# M051DN_v1 register map
File version: 1.0
Registers are 32-bit, read-write, reset 0x0 unless marked. A register's access mark holds for its fields unless they carry their own. Offsets are from the block's base; [hi:lo] are bit positions; 'fields as' and 'values as' point back to an identical list.

## SPI0 — SPI Register Map
Base 0x40030000
Same registers: SPI1 0x40034000
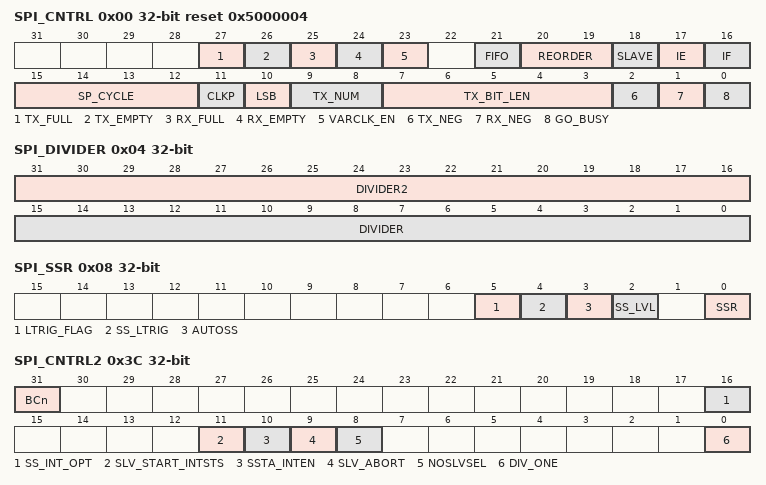
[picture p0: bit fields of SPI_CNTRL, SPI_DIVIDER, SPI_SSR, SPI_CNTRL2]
0x00 SPI_CNTRL reset 0x5000004 — Control and Status Register
  [27] TX_FULL ro — Transmit FIFO Buffer Full Indicator (Read Only) (M05xxDN/DE Only). It is a mutual mirror bit of SPI_STATUS[27].
    0=Indicates that the transmit FIFO buffer is not full; 1=Indicates that the transmit FIFO buffer is full
  [26] TX_EMPTY ro — Transmit FIFO Buffer Empty Indicator (Read Only) (M05xxDN/DE Only). It is a mutual mirror bit of SPI_STATUS[26].
    0=Indicates that the transmit FIFO buffer is not empty; 1=Indicates that the transmit FIFO buffer is empty
  [25] RX_FULL ro — Receive FIFO Buffer Full Indicator (Read Only) (M05xxDN/DE Only). It is a mutual mirror bit of SPI_STATUS[25].
    0=Indicates that the receive FIOF buffer is not full; 1=Indicates that the receive FIFO buffer is full
  [24] RX_EMPTY ro — Receive FIFO Buffer Empty Indicator (Read Only) (M05xxDN/DE Only). It is a mutual mirror bit of SPI_CNTRL[24].
    0=Indicates that the receive FIFO buffer is not empty; 1=Indicates that the receive FIFO buffer is empty
  [23] VARCLK_EN — Variable Clock Enable Control (M05xxBN Master Mode Only). Note: When this VARCLK_EN bit is set, the setting of TX_BIT_LEN must be programmed as 0x10 (16-bit mode).
    0=The bus clock output frequency is fixed and decided only by the value of DIVIDER; 1=The bus clock output frequency is variable. The output frequency is decided by the value of VARCLK, DIVIDER, and DIVIDER2
  [21] FIFO — FIFO Mode Enable Control (M05xxDN/DE Only). In Master mode, if the FIFO mode is enabled, the GO_BUSY bit will be set to 1 automatically after writing data into the 8-depth transmit FIFO. When all data stored at transmit FIFO buffer are transferred, the GO_BUSY bit will back to 0. Note 1: Before enabling FIFO mode, the other related settings should be set in advance. Note 2: On M05xxBN, this bit must be 0.
    0=FIFO Mode Disabled; 1=FIFO Mode Enabled
  [20:19] REORDER — Byte Reorder Function and Byte Suspend Function Selection. On M05xxBN: Note: Byte reorder function is only available if TX_BIT_LEN is defined as 16, 24, and 32 bits.
    0=Disable both byte reorder and byte suspend functions. Byte reorder function and byte suspend function are Disabled; 1=Enable byte reorder function and insert a byte suspend interval (2~17 SPICLK cycles) among each byte. The setting of TX_BIT_LEN must be configured as 0x00 (32 bits). Byte reorder function Enabled. Byte suspend interval is determined by the setting of SP_CYCLE. Set SP_CYCLE to 0 to disabled byte suspend function; 2=Enable byte reorder function, but disable byte suspend function. Reserved; 3=Disable byte reorder function, but insert a suspend interval (2~17 SPICLK cycles) among each byte. The setting of TX_BIT_LEN must be configured as 0x00 (32 bits). Reserved
  [18] SLAVE — Slave Mode Control
    0=Master mode; 1=Slave mode
  [17] IE — Unit-transfer Interrupt Enable Control
    0=SPI unit-transfer interrupt Disabled; 1=SPI unit-transfer interrupt Enabled
  [16] IF — Unit-transfer Interrupt Flag. Note: This bit will be cleared by writing 1 to itself.
    0=No transaction has been finished since this bit was cleared to 0; 1=SPI controller has finished one unit transfer
  [15:12] SP_CYCLE — Suspend Interval (Master Only). These four bits provide configurable suspend interval between two successive transactions in a transfer. The definition of the suspend interval is the interval between the last clock edge of the preceding transaction word and the first clock edge of the following transaction word. On M05xxBN:
  [11] CLKP — Clock Polarity
    0=SPICLK idle low; 1=SPICLK idle high
  [10] LSB — LSB First
    0=The MSB is transmitted/received first; 1=The LSB is transmitted/received first
  [9:8] TX_NUM — Numbers of Transmit/Receive Word (M05xxBN Only). This field specifies how many transmit/receive word numbers should be executed in one transfer. Note: In Slave mode with level-trigger configuration, if TX_NUM is set to 01, the slave select pin must be kept at active state during the successive data transfer.
    0=Burst mode Disabled. Only one word will be transferred when the GO_BUSY bit is set to 1; 1=Burst mode Enabled. Two successive words will be transferred when the GO_BUSY bit is set to 1
  [7:3] TX_BIT_LEN — Transfer Bit Length. This field specifies how many bits can be transmitted / received in one transaction. The minimum bit length is 8 bits and can up to 32 bits.
  [2] TX_NEG — Transmit on Negative Edge
    0=The transmitted data output signal is driven on the rising edge of SPICLK; 1=The transmitted data output signal is driven on the falling edge of SPICLK
  [1] RX_NEG — Receive on Negative Edge
    0=The received data input signal is latched on the rising edge of SPICLK; 1=The received data input signal is latched on the falling edge of SPICLK
  [0] GO_BUSY — SPI Transfer Trigger and Busy Status. On M05xxBN: During the data transfer, this bit keeps the value of 1. As the transfer is finished, this bit will be cleared automatically. Note 1: When FIFO mode is disabled, all configurations should be ready before writing 1 to the GO_BUSY bit. Note 2: In M05xxDN/DE SPI Slave mode, if FIFO mode is disabled and the SPI bus clock is kept at idle state during a data transfer, the GO_BUSY bit will not be cleared to 0 when slave select signal goes to inactive state.
    0=Writing 0 to this bit to stop data transfer if SPI is transferring; 1=In Master mode, writing 1 to this bit will start the SPI data transfer; in Slave mode, writing 1 to this bit indicates that the slave is ready to communicate with a master. In Master mode, writing 1 to this bit to start the SPI data transfer; in Slave mode, writing 1 to this bit indicates that the slave is ready to communicate with a master
0x04 SPI_DIVIDER — Clock Divider Register
  [31:16] DIVIDER2 — Clock Divider 2 (M05xxBN Master Mode Only). The value in this field is the 2nd frequency divider for generating the bus clock on the output SPICLK. The desired frequency is obtained according to the following equation: . If VARCLK_EN is cleared to 0, this setting is unmeaning.
  [15:0] DIVIDER — Clock Divider. On M05xxBN: Only available in Master mode. The value in this field is the frequency divider to determine the master's peripheral clock frequency and the bus clock frequency on the SPICLK output pin. The desired frequency is obtained according to the following equation: . In Slave mode, the period of SPI bus clock driven by a master shall equal or over 5 times the period of PCLK. In other words, the maximum frequency of SPI bus clock is the fifth of the frequency of slave's PCLK. . On M05xxDN/DE: Only DIVIDER[7:0] is available. The value in this field is the frequency divider to determine the SPI peripheral clock frequency, fspi, and the SPI master's bus clock frequency on the SPICLK output pin. The frequency is obtained according to the following equation. If the bit of BCn, SPI_CNTRL2[31], is set to 0, else if BCn is set to 1, where is the SPI peripheral clock source which is defined in the CLKSEL1 register.
0x08 SPI_SSR — Slave Select Register
  [5] LTRIG_FLAG — Level Trigger Flag. When the SS_LTRIG bit is set in Slave mode, this bit can be read to indicate the received bit number is met the requirement or not. Note: This bit is READ only and only available in Slave mode.
    0=The transaction number or the transferred bit length of one transaction does not meet the specified requirements; 1=The transaction number and the transferred bit length met the specified requirements which defined in TX_NUM and TX_BIT_LEN. The TX_NUM setting is not available on M05xxDN/DE, only the setting of TX_BIT_LEN will be considered
  [4] SS_LTRIG — Slave Select Level Trigger Enable (Slave Only)
    0=The input slave select signal is edge-trigger. This is the default value. It depends on SS_LVL to decide the signal is active at falling-edge or rising-edge; 1=The slave select signal will be level-trigger. It depends on SS_LVL to decide the signal is active low or active high
  [3] AUTOSS — Automatic Slave Select Function Enable (Master Only)
    0=If this bit is cleared, slave select signal will be asserted/de-asserted by setting /clearing SSR bit; 1=If this bit is set, SPISSx signal will be generated automatically, which means that slave select signal will be asserted by the SPI controller when transmit/receive is started by setting GO_BUSY, and will be de-asserted after each transmit/receive is finished
  [2] SS_LVL — Slave Select Active Level. This bit defines the active status of slave select signal (SPISSx).
    0=The slave select signal SPISSx is active at low-level/falling-edge; 1=The slave select signal SPISSx is active at high-level/rising-edge
  [0] SSR — Slave Select Control (Master Only). If AUTOSS bit is cleared to 0,
    0=Set the SPISSx line to inactive state. Keep the SPISSx line at inactive state; 1=Set the proper SPISSx line to active state. Select the SPISSx line to be automatically driven to active state for the duration of transmission/reception, and will be driven to inactive state for the rest of the time. The active state of SPISSx is specified in SS_LVL bit
0x10 SPI_RX0 ro — Data Receive Register 0
  [31:0] RX — Data Receive Register. The Data Receive Registers hold the value of received data of the last executed transfer. Valid bits depend on the transmit bit length field in the SPI_CNTRL register. For example, if TX_BIT_LEN is set to 0x08 and TX_NUM is set to 0x0, bit RX0[7:0] holds the received data. The values of the other bits are unknown. The Data Receive Registers are read-only registers.
0x14 SPI_RX1 ro — Data Receive Register 1 (M05xxBN Only)
  fields as SPI_RX0
0x20 SPI_TX0 wo — Data Transmit Register 0
  [31:0] TX — Data Transmit Register. The Data Transmit Registers hold the data to be transmitted in the next transfer. Valid bits depend on the transmit bit length field in the CNTRL register. For example, if TX_BIT_LEN is set to 0x08 and the TX_NUM is set to 0x0, the bit TX0[7:0] will be transmitted in next transfer. If TX_BIT_LEN is set to 0x00 and TX_NUM is set to 0x1, the SPI controller will perform two 32-bit transmit/receive successive using the same setting. The transmission sequence is TX0[31:0] first and then TX1[31:0].
0x24 SPI_TX1 wo — Data Transmit Register 1 (M05xxBN Only)
  fields as SPI_TX0
0x34 SPI_VARCLK reset 0x7FFF87 — Variable Clock Pattern Register (M05xxBN Only)
  [31:0] VARCLK — Variable Clock Pattern. The value in this field is the frequency patterns of the SPI bus clock. If the bit pattern of VARCLK is '0', the output frequency of SPICLK is according the value of DIVIDER. If the bit patterns of VARCLK are '1', the output frequency of SPICLK is according the value of DIVIDER2. Refer to the SPI_DIVIDER register. Note: Refer to the Variable Bus Clock Frequency paragraph for more detailed description.
0x3C SPI_CNTRL2 — Control and Status Register 2
  [31] BCn — Clock Configuration Backward Compatible Option (M05xxDN/DE Only). Refer to the description of SPI_DIVIDER register for details.
    0=The clock configuration is backward compatible to M05xxBN; 1=The clock configuration is not backward compatible to M05xxBN
  [16] SS_INT_OPT — Slave Select Inactive Interrupt Option (M05xxDN/DE Only). This setting is only available if the SPI controller is configured as level trigger slave device.
    0=As the slave select signal goes to inactive level, the IF bit will NOT be set to 1; 1=As the slave select signal goes to inactive level, the IF bit will be set to 1
  [11] SLV_START_INTSTS — Slave 3-wire Mode Start Interrupt Status. This bit dedicates if a transaction has started in Slave 3-wire mode. It is a mutual mirror bit of SPI_STATUS[11].
    0=Slave does not detect any SPI bus clock transition since the SSTA_INTEN bit was set to 1; 1=A transaction has started in Slave 3-wire mode. It will be cleared automatically when a transaction is done or by writing 1 to this bit
  [10] SSTA_INTEN — Slave 3-wire Mode Start Interrupt Enable. It is used to enable interrupt when the transfer has started in Slave 3-wire mode. If there is no transfer done interrupt over the time period which is defined by user after the transfer start, user can set the SLV_ABORT bit to force the transfer done.
    0=Transaction start interrupt Disabled; 1=Transaction start interrupt Enabled. It will be cleared to 0 as the current transfer is done or the SLV_START_INTSTS bit is cleared to 0
  [9] SLV_ABORT — Slave 3-wire Mode Abort Control. In normal operation, there is an interrupt event when the number of received bits meets the requirement which defined in TX_BIT_LEN and TX_NUM. The TX_NUM setting is not available on M05xxDN/DE, and only the setting of TX_BIT_LEN will be considered. If the number of received bits is less than the requirement and there is no more bus clock input over one transfer time in Slave 3-wire mode, user can set this bit to force the current transfer done and then user can get a unit transfer interrupt event. Note: This bit will be cleared to 0 automatically by hardware after it is set to 1 by software.
  [8] NOSLVSEL — Slave 3-wire Mode Enable. This is used to ignore the slave select signal in Slave mode. The SPI controller can work with 3-wire interface including SPICLK, SPI_MISO, and SPI_MOSI when this bit is set to 1. Note: In Slave 3-wire mode, the SS_LTRIG bit (SPI_SSR[4]) shall be set as 1.
    0=The controller is 4-wire bi-direction interface; 1=The controller is 3-wire bi-direction interface in Slave mode. When this bit is set to 1, the controller will be ready to transmit/receive data after the GO_BUSY bit is set to 1
  [0] DIV_ONE — SPI Bus Clock Divider Control (M05xxBN Master Mode Only). Note: When this bit is set to 1, both the REORDER field and the VARCLK_EN field must be configured as 0. In other words, the byte-reorder function, byte suspend function and variable clock function must be disabled.
    0=The SPI bus clock rate is determined by the setting of SPI_DIVIDER register; 1=Enable the DIV_ONE feature. The SPI bus clock rate equals the system clock rate
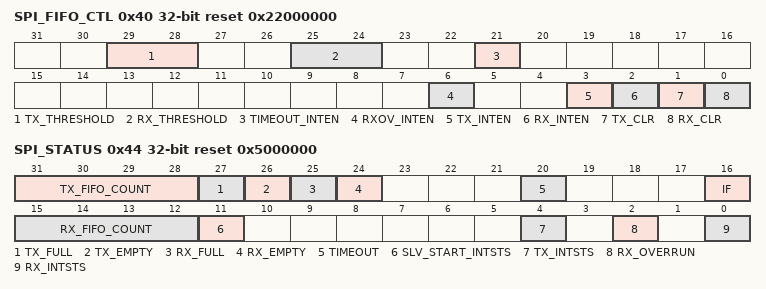
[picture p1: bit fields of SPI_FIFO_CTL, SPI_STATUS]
0x40 SPI_FIFO_CTL reset 0x22000000 — SPI FIFO Control Register (M05xxDN/DE Only)
  [29:28] TX_THRESHOLD — Transmit FIFO Threshold. If the valid data count of the transmit FIFO buffer is less than or equal to the TX_THRESHOLD setting, the TX_INTSTS bit will be set to 1, else the TX_INTSTS bit will be cleared to 0.
  [25:24] RX_THRESHOLD — Received FIFO Threshold. If the valid data count of the receive FIFO buffer is larger than the RX_THRESHOLD setting, the RX_INTSTS bit will be set to 1, else the RX_INTSTS bit will be cleared to 0.
  [21] TIMEOUT_INTEN — Receive FIFO Time-out Interrupt Enable Control
    0=Time-out interrupt Disabled; 1=Time-out interrupt Enabled
  [6] RXOV_INTEN — Receive FIFO Overrun Interrupt Enable Control
    0=Receive FIFO overrun interrupt Disabled; 1=Receive FIFO overrun interrupt Enabled
  [3] TX_INTEN — Transmit Threshold Interrupt Enable Control
    0=Transmit threshold interrupt Disabled; 1=Transmit threshold interrupt Enabled
  [2] RX_INTEN — Receive Threshold Interrupt Enable Control
    0=Receive threshold interrupt Disabled; 1=Receive threshold interrupt Enabled
  [1] TX_CLR — Clear Transmit FIFO Buffer
    0=No effect; 1=Clear transmit FIFO buffer. The TX_FULL flag will be cleared to 0 and the TX_EMPTY flag will be set to 1. This bit will be cleared to 0 by hardware after software sets it to 1 and the transmit FIFO is cleared
  [0] RX_CLR — Clear Receive FIFO Buffer
    0=No effect; 1=Clear receive FIFO buffer. The RX_FULL flag will be cleared to 0 and the RX_EMPTY flag will be set to 1. This bit will be cleared to 0 by hardware after software sets it to 1 and the receive FIFO is cleared
0x44 SPI_STATUS reset 0x5000000 — SPI Status Register (M05xxDN/DE Only)
  [31:28] TX_FIFO_COUNT ro — Transmit FIFO Data Count (Read Only). Indicates the valid data count of transmit FIFO buffer.
  [27] TX_FULL ro — Transmit FIFO Buffer Full Indicator (Read Only). It is a mutual mirror bit of SPI_CNTRL[27].
    0=The transmit FIFO buffer is not full; 1=The transmit FIFO buffer is full
  [26] TX_EMPTY ro — Transmit FIFO Buffer Empty Indicator (Read Only). It is a mutual mirror bit of SPI_CNTRL[26].
    0=The transmit FIFO buffer is not empty; 1=The transmit FIFO buffer is empty
  [25] RX_FULL ro — Receive FIFO Buffer Full Indicator (Read Only). It is a mutual mirror bit of SPI_CNTRL[25].
    0=The receive FIFO buffer is not full; 1=The receive FIFO buffer is full
  [24] RX_EMPTY ro — Receive FIFO Buffer Empty Indicator (Read Only). It is a mutual mirror bit of SPI_CNTRL[24].
    0=The receive FIFO buffer is not empty; 1=The receive FIFO buffer is empty
  [20] TIMEOUT — Time-out Interrupt Flag. Note: This bit will be cleared by writing 1 to itself.
    0=No receive FIFO time-out event; 1=The receive FIFO buffer is not empty and it does not be read over 64 SPI clock periods in Master mode or over 576 SPI peripheral clock periods in Slave mode. When the received FIFO buffer is read by software, the time-out status will be cleared automatically
  [16] IF — SPI Unit-transfer Interrupt Flag. It is a mutual mirror bit of SPI_CNTRL[16]. Note: This bit will be cleared by writing 1 to itself.
    0=The transfer does not finish yet; 1=The SPI controller has finished one unit transfer
  [15:12] RX_FIFO_COUNT ro — Receive FIFO Data Count (Read Only). Indicates the valid data count of receive FIFO buffer.
  [11] SLV_START_INTSTS — Slave Start Interrupt Status. It is used to dedicate that the transfer has started in Slave 3-wire mode. It's a mutual mirror bit of SPI_CNTRL2[11].
    0=The transfer is not started; 1=The transfer has started in Slave 3-wire mode. It will be cleared as transfer done or by writing one to this bit
  [4] TX_INTSTS ro — Transmit FIFO Threshold Interrupt Status (Read Only)
    0=The valid data count within the transmit FIFO buffer is larger than the setting value of TX_THRESHOLD; 1=The valid data count within the transmit FIFO buffer is less than or equal to the setting value of TX_THRESHOLD
  [2] RX_OVERRUN — Receive FIFO Overrun Status. When the receive FIFO buffer is full, the follow-up data will be dropped and this bit will be set to 1. Note: This bit will be cleared by writing 1 to itself.
  [0] RX_INTSTS ro — Receive FIFO Threshold Interrupt Status (Read Only)
    0=The valid data count within the Rx FIFO buffer is smaller than or equal to the setting value of RX_THRESHOLD; 1=The valid data count within the receive FIFO buffer is larger than the setting value of RX_THRESHOLD
